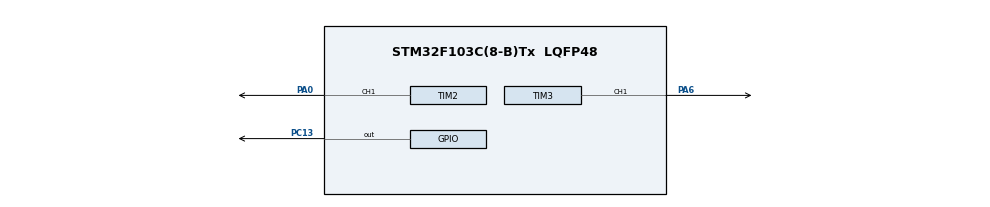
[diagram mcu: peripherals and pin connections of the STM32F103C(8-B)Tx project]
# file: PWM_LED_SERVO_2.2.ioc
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Mcu.Family=STM32F1
Mcu.Name=STM32F103C(8-B)Tx
Mcu.Package=LQFP48
NVIC.PriorityGroup=NVIC_PRIORITYGROUP_4
NVIC.TIM4_IRQn=true\:0\:0\:false\:false\:true\:true\:true\:true
PA0-WKUP.Signal=S_TIM2_CH1_ETR
PA13.Mode=Serial_Wire
PA13.Signal=SYS_JTMS-SWDIO
PA14.Mode=Serial_Wire
PA14.Signal=SYS_JTCK-SWCLK
PA6.Signal=S_TIM3_CH1
PC13-TAMPER-RTC.Signal=GPIO_Output
ProjectManager.HeapSize=0x200
ProjectManager.StackSize=0x400
ProjectManager.TargetToolchain=MDK-ARM V5.32
RCC.APB1Freq_Value=8000000
RCC.APB2Freq_Value=8000000
SH.S_TIM2_CH1_ETR.0=TIM2_CH1,PWM Generation1 CH1
SH.S_TIM3_CH1.0=TIM3_CH1,PWM Generation1 CH1
TIM2.Channel-PWM\ Generation1\ CH1=TIM_CHANNEL_1
TIM2.Period=999
TIM2.Prescaler=7
TIM3.Channel-PWM\ Generation1\ CH1=TIM_CHANNEL_1
TIM3.Period=199
TIM3.Prescaler=799
TIM4.Period=99
TIM4.Prescaler=799
VP_TIM2_VS_ClockSourceINT.Mode=Internal
VP_TIM3_VS_ClockSourceINT.Mode=Internal
VP_TIM4_VS_ClockSourceINT.Mode=Internal
board=custom

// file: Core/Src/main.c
/* USER CODE BEGIN Header */
/**
  ******************************************************************************
  * @file           : main.c
  * @brief          : Main program body
  ******************************************************************************
  * @attention
  *
  * Copyright (c) 2026 STMicroelectronics.
  * All rights reserved.
  *
  * This software is licensed under terms that can be found in the LICENSE file
  * in the root directory of this software component.
  * If no LICENSE file comes with this software, it is provided AS-IS.
  *
  ******************************************************************************
  */
/* USER CODE END Header */
#include "main.h"

TIM_HandleTypeDef htim2;
TIM_HandleTypeDef htim3;
TIM_HandleTypeDef htim4;

/* USER CODE BEGIN PV */
volatile uint8_t servo_flag = 0;//舵机转动标志
volatile uint8_t LED_flag = 0;//呼吸灯标志
uint16_t servo_ccr =5;//舵机的ccr值
uint16_t angle = 0; //角度初始值
int16_t angle_step = 1;//单次转动角度
uint16_t LED_ccr = 0;//呼吸灯的ccr
uint16_t LED_step = 2;//呼吸灯的单次改变值
/* USER CODE END PV */

void SystemClock_Config(void);
static void MX_GPIO_Init(void);
static void MX_TIM2_Init(void);
static void MX_TIM3_Init(void);
static void MX_TIM4_Init(void);

int main(void)
{

  /* MCU Configuration--------------------------------------------------------*/

  /* Reset of all peripherals, Initializes the Flash interface and the Systick. */
  HAL_Init();

  /* Configure the system clock */
  SystemClock_Config();

  /* Initialize all configured peripherals */
  MX_GPIO_Init();
  MX_TIM2_Init();
  MX_TIM3_Init();
  MX_TIM4_Init();
  /* USER CODE BEGIN 2 */
  HAL_TIM_PWM_Start(&htim2, TIM_CHANNEL_1);
  HAL_TIM_PWM_Start(&htim3, TIM_CHANNEL_1);
  HAL_TIM_Base_Start_IT(&htim4);
  /* USER CODE END 2 */

  /* Infinite loop */
  /* USER CODE BEGIN WHILE */
  while (1)
  {
    //舵机
    if(servo_flag == 1)
    {
      servo_flag = 0;
      angle += angle_step;
      if(angle >= 180)
      {
        angle_step = -angle_step;
        angle = 180;
      }
      if(angle <= 0)
      {
        angle_step = -angle_step;
        angle = 0;
      }
      servo_ccr = 5 + angle/9;
      __HAL_TIM_SetCompare(&htim3, TIM_CHANNEL_1,servo_ccr);
    }
    //呼吸灯
    if(LED_flag == 1)
    {
      LED_flag = 0;
      LED_ccr += LED_step ;
      if(LED_ccr >= 1000)
      {
        LED_step = -LED_step;
      }
      if(LED_ccr <= 0)
      {
        LED_step = -LED_step;
      }
      __HAL_TIM_SET_COMPARE(&htim2, TIM_CHANNEL_1, LED_ccr);
    }
    /* USER CODE END WHILE */

  }
}

void SystemClock_Config(void)
{
  RCC_OscInitTypeDef RCC_OscInitStruct = {0};
  RCC_ClkInitTypeDef RCC_ClkInitStruct = {0};

  /** Initializes the RCC Oscillators according to the specified parameters
  * in the RCC_OscInitTypeDef structure.
  */
  RCC_OscInitStruct.OscillatorType = RCC_OSCILLATORTYPE_HSI;
  RCC_OscInitStruct.HSIState = RCC_HSI_ON;
  RCC_OscInitStruct.HSICalibrationValue = RCC_HSICALIBRATION_DEFAULT;
  RCC_OscInitStruct.PLL.PLLState = RCC_PLL_NONE;
  if (HAL_RCC_OscConfig(&RCC_OscInitStruct) != HAL_OK)
  {
    Error_Handler();
  }

  /** Initializes the CPU, AHB and APB buses clocks
  */
  RCC_ClkInitStruct.ClockType = RCC_CLOCKTYPE_HCLK|RCC_CLOCKTYPE_SYSCLK
                              |RCC_CLOCKTYPE_PCLK1|RCC_CLOCKTYPE_PCLK2;
  RCC_ClkInitStruct.SYSCLKSource = RCC_SYSCLKSOURCE_HSI;
  RCC_ClkInitStruct.AHBCLKDivider = RCC_SYSCLK_DIV1;
  RCC_ClkInitStruct.APB1CLKDivider = RCC_HCLK_DIV1;
  RCC_ClkInitStruct.APB2CLKDivider = RCC_HCLK_DIV1;

  if (HAL_RCC_ClockConfig(&RCC_ClkInitStruct, FLASH_LATENCY_0) != HAL_OK)
  {
    Error_Handler();
  }
}

static void MX_TIM2_Init(void)
{

  TIM_ClockConfigTypeDef sClockSourceConfig = {0};
  TIM_MasterConfigTypeDef sMasterConfig = {0};
  TIM_OC_InitTypeDef sConfigOC = {0};

  htim2.Instance = TIM2;
  htim2.Init.Prescaler = 7;
  htim2.Init.CounterMode = TIM_COUNTERMODE_UP;
  htim2.Init.Period = 999;
  htim2.Init.ClockDivision = TIM_CLOCKDIVISION_DIV1;
  htim2.Init.AutoReloadPreload = TIM_AUTORELOAD_PRELOAD_DISABLE;
  if (HAL_TIM_Base_Init(&htim2) != HAL_OK)
  {
    Error_Handler();
  }
  sClockSourceConfig.ClockSource = TIM_CLOCKSOURCE_INTERNAL;
  if (HAL_TIM_ConfigClockSource(&htim2, &sClockSourceConfig) != HAL_OK)
  {
    Error_Handler();
  }
  if (HAL_TIM_PWM_Init(&htim2) != HAL_OK)
  {
    Error_Handler();
  }
  sMasterConfig.MasterOutputTrigger = TIM_TRGO_RESET;
  sMasterConfig.MasterSlaveMode = TIM_MASTERSLAVEMODE_DISABLE;
  if (HAL_TIMEx_MasterConfigSynchronization(&htim2, &sMasterConfig) != HAL_OK)
  {
    Error_Handler();
  }
  sConfigOC.OCMode = TIM_OCMODE_PWM1;
  sConfigOC.Pulse = 0;
  sConfigOC.OCPolarity = TIM_OCPOLARITY_HIGH;
  sConfigOC.OCFastMode = TIM_OCFAST_DISABLE;
  if (HAL_TIM_PWM_ConfigChannel(&htim2, &sConfigOC, TIM_CHANNEL_1) != HAL_OK)
  {
    Error_Handler();
  }
  HAL_TIM_MspPostInit(&htim2);

}

static void MX_TIM3_Init(void)
{

  TIM_ClockConfigTypeDef sClockSourceConfig = {0};
  TIM_MasterConfigTypeDef sMasterConfig = {0};
  TIM_OC_InitTypeDef sConfigOC = {0};

  htim3.Instance = TIM3;
  htim3.Init.Prescaler = 799;
  htim3.Init.CounterMode = TIM_COUNTERMODE_UP;
  htim3.Init.Period = 199;
  htim3.Init.ClockDivision = TIM_CLOCKDIVISION_DIV1;
  htim3.Init.AutoReloadPreload = TIM_AUTORELOAD_PRELOAD_DISABLE;
  if (HAL_TIM_Base_Init(&htim3) != HAL_OK)
  {
    Error_Handler();
  }
  sClockSourceConfig.ClockSource = TIM_CLOCKSOURCE_INTERNAL;
  if (HAL_TIM_ConfigClockSource(&htim3, &sClockSourceConfig) != HAL_OK)
  {
    Error_Handler();
  }
  if (HAL_TIM_PWM_Init(&htim3) != HAL_OK)
  {
    Error_Handler();
  }
  sMasterConfig.MasterOutputTrigger = TIM_TRGO_RESET;
  sMasterConfig.MasterSlaveMode = TIM_MASTERSLAVEMODE_DISABLE;
  if (HAL_TIMEx_MasterConfigSynchronization(&htim3, &sMasterConfig) != HAL_OK)
  {
    Error_Handler();
  }
  sConfigOC.OCMode = TIM_OCMODE_PWM1;
  sConfigOC.Pulse = 0;
  sConfigOC.OCPolarity = TIM_OCPOLARITY_HIGH;
  sConfigOC.OCFastMode = TIM_OCFAST_DISABLE;
  if (HAL_TIM_PWM_ConfigChannel(&htim3, &sConfigOC, TIM_CHANNEL_1) != HAL_OK)
  {
    Error_Handler();
  }
  HAL_TIM_MspPostInit(&htim3);

}

static void MX_TIM4_Init(void)
{

  TIM_ClockConfigTypeDef sClockSourceConfig = {0};
  TIM_MasterConfigTypeDef sMasterConfig = {0};

  htim4.Instance = TIM4;
  htim4.Init.Prescaler = 799;
  htim4.Init.CounterMode = TIM_COUNTERMODE_UP;
  htim4.Init.Period = 99;
  htim4.Init.ClockDivision = TIM_CLOCKDIVISION_DIV1;
  htim4.Init.AutoReloadPreload = TIM_AUTORELOAD_PRELOAD_DISABLE;
  if (HAL_TIM_Base_Init(&htim4) != HAL_OK)
  {
    Error_Handler();
  }
  sClockSourceConfig.ClockSource = TIM_CLOCKSOURCE_INTERNAL;
  if (HAL_TIM_ConfigClockSource(&htim4, &sClockSourceConfig) != HAL_OK)
  {
    Error_Handler();
  }
  sMasterConfig.MasterOutputTrigger = TIM_TRGO_RESET;
  sMasterConfig.MasterSlaveMode = TIM_MASTERSLAVEMODE_DISABLE;
  if (HAL_TIMEx_MasterConfigSynchronization(&htim4, &sMasterConfig) != HAL_OK)
  {
    Error_Handler();
  }

}

static void MX_GPIO_Init(void)
{
  GPIO_InitTypeDef GPIO_InitStruct = {0};

  /* GPIO Ports Clock Enable */
  __HAL_RCC_GPIOC_CLK_ENABLE();
  __HAL_RCC_GPIOA_CLK_ENABLE();

  /*Configure GPIO pin Output Level */
  HAL_GPIO_WritePin(GPIOC, GPIO_PIN_13, GPIO_PIN_RESET);

  /*Configure GPIO pin : PC13 */
  GPIO_InitStruct.Pin = GPIO_PIN_13;
  GPIO_InitStruct.Mode = GPIO_MODE_OUTPUT_PP;
  GPIO_InitStruct.Pull = GPIO_NOPULL;
  GPIO_InitStruct.Speed = GPIO_SPEED_FREQ_LOW;
  HAL_GPIO_Init(GPIOC, &GPIO_InitStruct);

}

/* USER CODE BEGIN 4 */
void HAL_TIM_PeriodElapsedCallback(TIM_HandleTypeDef * htim)
{
  if(htim == &htim4)//中断10ms一次
  {
    servo_flag = 1;
    LED_flag = 1;
  }
}
/* USER CODE END 4 */

void Error_Handler(void)
{
  __disable_irq();
  while (1)
  {
  }
}
